# A31S13x register map
Vendor: VENDOR ABOV Semiconductor Co., Ltd.; Series: A31S13x; File version: 1.0
CPU: CM0+ r0p1, little endian, no MPU, no FPU, VTOR, 2 interrupt priority bits
Registers are 32-bit, read-write, reset 0x0 unless marked. A register's access mark holds for its fields unless they carry their own. Offsets are from the block's base; [hi:lo] are bit positions; {n}, {i} and the like mark numbered series; 'fields as' and 'values as' point back to an identical list.

## COA0 — Configuration Option Area Page 0: System Related Trimming Value
Base 0x1FFFF000
{0x0+4i} TRIM{i:02} ro reset not defined (i=0..19) — System Related Trim Value {i:02}
0x50 CONF_MF1CNFIG ro reset not defined — Manufacture Information 1
  [31:0] XYCDN — X and Y Coordinates
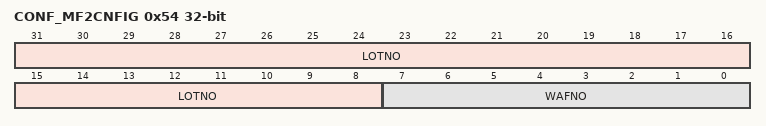
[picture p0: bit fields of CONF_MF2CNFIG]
0x54 CONF_MF2CNFIG ro reset not defined — Manufacture Information 2
  [31:8] LOTNO — Lot Number [23:0]
  [7:0] WAFNO — Wafer Number
0x58 CONF_MF3CNFIG ro reset not defined — Manufacture Information 3
  [31:0] LOTNO — Lot Number [55:24]
0x5C CONF_MF4CNFIG ro reset not defined — Manufacture Information 4
  [31:0] LOTNO — Lot Number [87:56]
{0x0+4i} TRIM{i} ro reset not defined (i=24..31) — System Related Trim Value {i}

## COA1 — Configuration Option Area Page 1: User Option
Base 0x1FFFF200
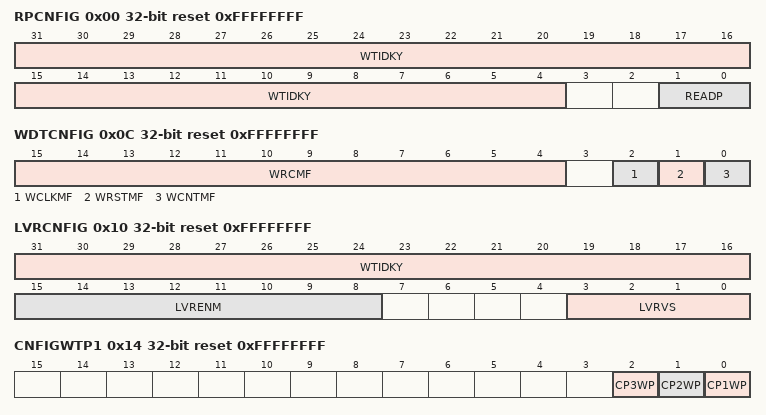
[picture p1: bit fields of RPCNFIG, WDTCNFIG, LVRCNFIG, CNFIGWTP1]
0x00 RPCNFIG ro reset 0xFFFFFFFF (reset mask 0xFFFFFFFC) — Configuration for Read Protection
  [31:4] WTIDKY — Write Identification Key (0x69c8a27)
    0x69C8A27=Value (Key Value (0x69c8a27))
  [1:0] READP — Read Protection for Flash Memory and Data Flash Memory Area
    3=Level0 (No restriction for read/erase/write.); 2=Level1 (1. Not readable/erasable/writable by 'Debug' 2. Bulk erasable only by 'Debug' 3. Readable/erasable/writable by 'Instruction from Flash Memory and RAM'); 0=Level2 (1. Not readable/erasable/writable by 'Debug' / 'Instruction from RAM' 2. Bulk erasable only by 'Instruction from RAM' / 'Debug' 3. Readable/erasable/writable by 'Instruction from Flash Memory')
0x0C WDTCNFIG ro reset 0xFFFFFFFF (reset mask 0xFFFF0008) — Configuration for Watch-Dog Timer
  [15:4] WRCMF — Watch-Dog Timer RC Oscillator Master Configuration
    0x96D=By S/W (CLKSRCR Register) (0x96d); 0x2A7=AlwaysEnableExceptDeepSleep (Always Enable Except for Deep Sleep (0x2a7)); 0xFFF=AlwaysEnable
  [2] WCLKMF — Watch-Dog Timer Clock Selection Master Configuration
    0=By S/W (PPCLKSR Register); 1=AlwaysWDTRC
  [1] WRSTMF — Watch-Dog Timer Reset Enable Master Configuration
    0=AlwaysEnable; 1=By S/W (WDTCR Register)
  [0] WCNTMF — Watch-Dog Timer Counter Enable Master Configuration
    0=AlwaysEnable; 1=By S/W (WDTCR Register)
0x10 LVRCNFIG ro reset 0xFFFFFFFF (reset mask 0xFFFF00F0) — Configuration for Low Voltage Reset
  [31:16] WTIDKY — Write Identification Key (0x9D58)
    0x9D58=Value (Key Value (0x9D58))
  [15:8] LVRENM — LVR Reset Operation Control Master Configuration
    170=By S/W (LVRCR Register) (0xaa); 255=Always Enable (0xff)
  [3:0] LVRVS — LVR Voltage Selection
    15=1p62V (1.62V); 14=DNW14 (Do not write.); 13=DNW13 (Do not write.); 12=DNW12 (Do not write.); 11=2p00V (2.00V); 10=2p13V (2.13V); 9=2p28V (2.28V); 8=2p46V (2.46V); 7=2p67V (2.67V); 6=3p04V (3.04V); 5=3p20V (3.20V); 4=3p55V (3.55V); 3=3p75V (3.75V); 2=3p99V (3.99V); 1=4p25V (4.25V); 0=4p55 (4.55V)
0x14 CNFIGWTP1 ro reset 0xFFFFFFFF (reset mask 0xFFFFFFF8) — Configure Option Page Erase/Write Protection 1
  [all] fields
    0=Enable protection. (Not erasable/writable by instruction); 1=Disable protection. (Erasable/writable by instruction)
  [2] CP3WP — Configure Option Page 3 Erase/Write Protection
  [1] CP2WP — Configure Option Page 2 Erase/Write Protection
  [0] CP1WP — Configure Option Page 1 Erase/Write Protection
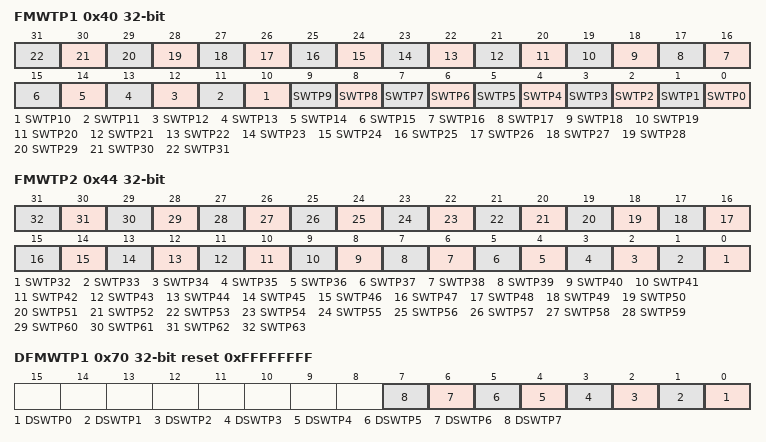
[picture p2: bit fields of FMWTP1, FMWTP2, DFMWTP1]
0x40 FMWTP1 ro reset not defined — Flash Memory Erase/Write Protection 1
  [all] fields
    0=Enable (Protect 'flash memory sector n erase/write'); 1=Disable (Permit 'flash memory sector n erase/write')
  [n] SWTP{n} (n=0..31) — Flash Memory Erase/Write Protection {n}
0x44 FMWTP2 ro reset not defined — Flash Memory Erase/Write Protection 2
  [all] fields
    values as the fields of FMWTP1
  [n-32] SWTP{n} (n=32..63) — Flash Memory Erase/Write Protection {n}
0x70 DFMWTP1 ro reset 0xFFFFFFFF (reset mask 0xFFFFFF00) — Data Flash Memory Erase/Write Protection 1
  [all] fields
    values as the fields of FMWTP1
  [n] DSWTP{n} (n=0..7) — Data Flash Memory Erase/Write Protection {n}

## COA2 — Configuration Option Area Page 2: User Data Area 0
Base 0x1FFFF400
Same registers: COA3 0x1FFFF600
{0x0+4i} UDATA{i:02} ro reset not defined (i=0..63) — User Data {i:02}
